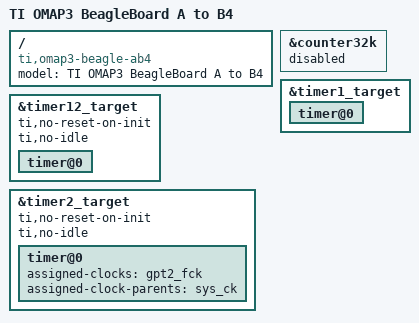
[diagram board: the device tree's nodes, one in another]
// SPDX-License-Identifier: GPL-2.0-only
/dts-v1/;

#include "omap3-beagle.dts"

/ {
	model = "TI OMAP3 BeagleBoard A to B4";
	compatible = "ti,omap3-beagle-ab4", "ti,omap3-beagle", "ti,omap3430", "ti,omap3";
};

/*
 * Workaround for capacitor C70 issue, see "Boards revision A and < B5"
 * section at https://elinux.org/BeagleBoard_Community
 */

/* Unusable as clocksource because of unreliable oscillator */
&counter32k {
	status = "disabled";
};

/* Unusable as clockevent because of unreliable oscillator, allow to idle */
&timer1_target {
	/delete-property/ti,no-reset-on-init;
	/delete-property/ti,no-idle;
	timer@0 {
		/delete-property/ti,timer-alwon;
	};
};

/* Preferred always-on timer for clocksource */
&timer12_target {
	ti,no-reset-on-init;
	ti,no-idle;
	timer@0 {
		/* Always clocked by secure_32k_fck */
	};
};

/* Preferred timer for clockevent */
&timer2_target {
	ti,no-reset-on-init;
	ti,no-idle;
	timer@0 {
		assigned-clocks = <&gpt2_fck>;
		assigned-clock-parents = <&sys_ck>;
	};
};
